AUTOSAR XML (schema 4-2-1)
package /ComponentTypes
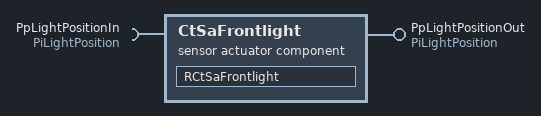
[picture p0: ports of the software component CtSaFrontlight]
  sensor actuator sw component type CtSaFrontlight
    provide port PpLightPositionOut: provided-com-specs=[{data-element=DeLightLength, init-value=0}, {data-element=DeLightPosition, init-value=0}], provided-interface=PiLightPosition
    require port PpLightPositionIn: required-interface=PiLightPosition
      required-com-specs:
        data-element=DeLightLength, filter=data-filter-type=ALWAYS, init-value=0
        data-element=DeLightPosition, filter=data-filter-type=ALWAYS, init-value=0
    behavior CtSaFrontlight_InternalBehavior: data-type-mapping=ApMappingSet, supports-multiple-instantiation=true
      data received event DRT_RCtSaHeadlight_PpLightPosition_DeLightPosition: start-on-event=RCtSaFrontlight, data=PpLightPositionIn.DeLightPosition
      runnable RCtSaFrontlight
        data-receive-point-by-arguments:
          access REC_PpLightPosition_DeLightPosition: accessed-variable=PpLightPositionIn.DeLightPosition
          access REC_PpLightPositionIn_DeLightMode: accessed-variable=PpLightPositionIn.DeLightLength
        data-send-points:
          access SEND_PpLightPositionOut_DeLightMode: accessed-variable=PpLightPositionOut.DeLightLength
          access SEND_PpLightPositionOut_DeLightPosition: accessed-variable=PpLightPositionOut.DeLightPosition
  swc implementation CtSaFrontlight_Implementation: behavior=CtSaFrontlight_InternalBehavior
    code-descriptors:
      code Default: artifact-descriptors=autosar-engineering-object={short-label=Default, category=SWSRC}
